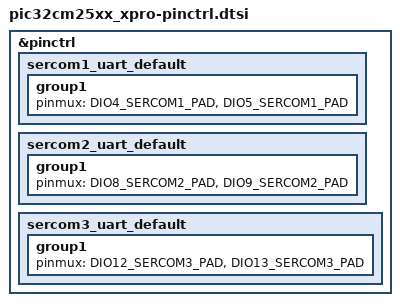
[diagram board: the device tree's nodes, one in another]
/*
 * Copyright (c) 2024 Microchip Technology Inc
 *
 * SPDX-License-Identifier: Apache-2.0
 */

#include <dt-bindings/pinctrl/pic32-cm25xx-pinctrl.h>

&pinctrl {
	sercom1_uart_default: sercom1_uart_default {
		group1 {
			pinmux = <DIO4_SERCOM1_PAD>,
				 <DIO5_SERCOM1_PAD>;
		};
	};

	sercom2_uart_default: sercom2_uart_default {
		group1 {
			pinmux = <DIO8_SERCOM2_PAD>,
				 <DIO9_SERCOM2_PAD>;
		};
	};

	sercom3_uart_default: sercom3_uart_default {
		group1 {
			pinmux = <DIO12_SERCOM3_PAD>,
				 <DIO13_SERCOM3_PAD>;
		};
	};
};
